AUTOSAR XML (schema 00051)
package /ComponentTypes
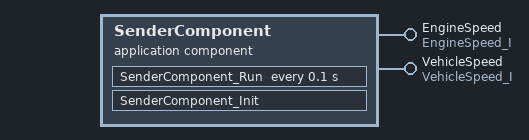
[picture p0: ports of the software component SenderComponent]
  application sw component type SenderComponent
    provide port EngineSpeed: nonqueued-sender-com-spec{data-element=EngineSpeed, init-value=constant-reference=EngineSpeed_IV}, provided-interface=EngineSpeed_I
    provide port VehicleSpeed: nonqueued-sender-com-spec{data-element=VehicleSpeed, init-value=constant-reference=VehicleSpeed_IV}, provided-interface=VehicleSpeed_I
    behavior SenderComponent_InternalBehavior
      exclusive area ExampleExclusiveArea
      init event IT_SenderComponent_Init: start-on-event=SenderComponent_Init
      timing event TMT_SenderComponent_Run: start-on-event=SenderComponent_Run, period=0.1
      port-api-options:
        enable-take-address=false, indirect-api=false, port=EngineSpeed
        enable-take-address=true, indirect-api=false, port=VehicleSpeed
      runnable SenderComponent_Init
      runnable SenderComponent_Run: can-enters=ExampleExclusiveArea
        data-send-points:
          access SEND_EngineSpeed_EngineSpeed: accessed-variable=EngineSpeed.EngineSpeed
          access SEND_VehicleSpeed_VehicleSpeed: accessed-variable=VehicleSpeed.VehicleSpeed
  swc implementation SenderComponent_Implementation: behavior=SenderComponent_InternalBehavior
